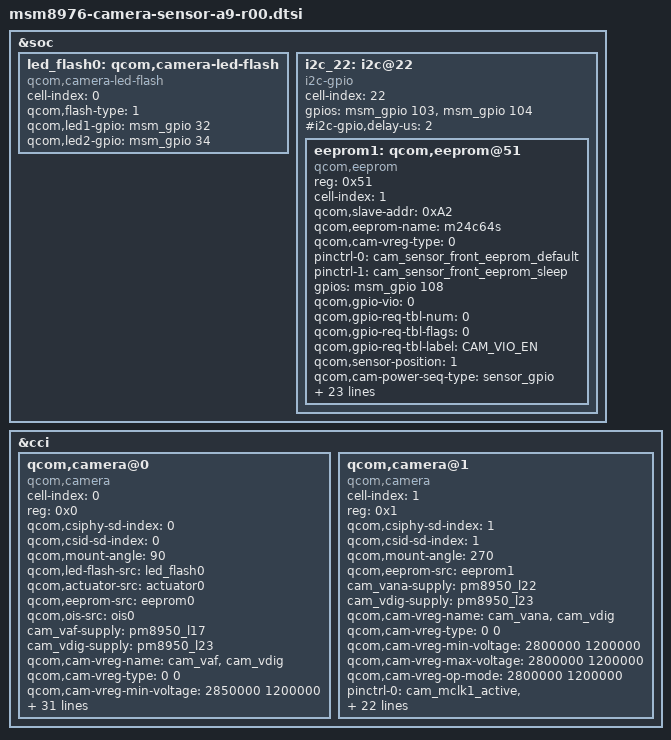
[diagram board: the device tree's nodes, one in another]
/*
 * Copyright (c) 2015, The Linux Foundation. All rights reserved.
 *
 * This program is free software; you can redistribute it and/or modify
 * it under the terms of the GNU General Public License version 2 and
 * only version 2 as published by the Free Software Foundation.
 *
 * This program is distributed in the hope that it will be useful,
 * but WITHOUT ANY WARRANTY; without even the implied warranty of
 * MERCHANTABILITY or FITNESS FOR A PARTICULAR PURPOSE.  See the
 * GNU General Public License for more details.
 */

&soc {

    led_flash0: qcom,camera-led-flash {
	cell-index = <0>;
	compatible = "qcom,camera-led-flash";
	qcom,flash-type = <1>;
	qcom,led1-gpio = <&msm_gpio 32 0x00>;
	qcom,led2-gpio = <&msm_gpio 34 0x00>;
    };
    i2c_22: i2c@22 {
	cell-index = <22>;
        compatible = "i2c-gpio";
	gpios = <&msm_gpio 103 0 /* sda */
                 &msm_gpio 104 0 /* scl */
		 >;
        #i2c-gpio,delay-us = <2>;
        #address-cells = <1>;
        #size-cells = <0>;

	eeprom1: qcom,eeprom@51 {
		 compatible = "qcom,eeprom";
		 reg = <0x51>;
		 cell-index = <1>;
		 qcom,slave-addr = <0xA2>;
		 qcom,eeprom-name = "m24c64s";
		 qcom,cam-vreg-type = <0>;
		 pinctrl-names = "cam_default", "cam_suspend";
		 pinctrl-0 = <&cam_sensor_front_eeprom_default>;
		 pinctrl-1 = <&cam_sensor_front_eeprom_sleep>;
		 gpios = <&msm_gpio 108 0>;
		 qcom,gpio-vio = <0>;
		 qcom,gpio-req-tbl-num = <0>;
		 qcom,gpio-req-tbl-flags = <0>;
		 qcom,gpio-req-tbl-label = "CAM_VIO_EN";
		 qcom,sensor-position = <1>;
		 qcom,cam-power-seq-type = "sensor_gpio";
		 qcom,cam-power-seq-val = "sensor_gpio_vio";
		 qcom,cam-power-seq-cfg-val = <1>;
		 qcom,cam-power-seq-delay =   <1>;
		 qcom,num-blocks = <6>;
		 qcom,page0 = <0 0x0 0 0x0 0 0>;
		 qcom,poll0 = <0 0x0 0 0x0 0 0>;
		 qcom,mem0 = <0x60 0x0 2 0 1 0>;
		 qcom,page1 = <0 0x0 0 0x0 0 0>;
		 qcom,poll1 = <0 0x0 0 0x0 0 0>;
		 qcom,mem1 = <4 0xFC 2 0 1 0>;
		 qcom,page2 = <0 0x0 0 0x0 0 0>;
		 qcom,poll2 = <0 0x0 0 0x0 0 0>;
		 qcom,mem2 = <0x20 0x200 2 0 1 0>;
		 qcom,page3 = <0 0x0 0 0x0 0 0>;
		 qcom,poll3 = <0 0x0 0 0x0 0 0>;
		 qcom,mem3 = <4 0x2FC 2 0 1 0>;
		 qcom,page4 = <0 0x0 0 0x0 0 0>;
		 qcom,poll4 = <0 0x0 0 0x0 0 0>;
		 qcom,mem4 = <0x700 0x300 2 0 1 0>;
		 qcom,page5 = <0 0x0 0 0x0 0 0>;
		 qcom,poll5 = <0 0x0 0 0x0 0 0>;
		 qcom,mem5 = <4 0xAFC 2 0 1 0>;
		 qcom,total-size = <0xB00>;

	         };
	};
};

&cci {

  qcom,camera@0 {
    cell-index = <0>;
    compatible = "qcom,camera";
    reg = <0x0>;
    qcom,csiphy-sd-index = <0>;
    qcom,csid-sd-index = <0>;
    qcom,mount-angle = <90>;
    qcom,led-flash-src = <&led_flash0>;
    qcom,actuator-src = <&actuator0>;
    qcom,eeprom-src = <&eeprom0>;
    qcom,ois-src = <&ois0>;
    cam_vaf-supply = <&pm8950_l17>;
    cam_vdig-supply = <&pm8950_l23>;
    qcom,cam-vreg-name = "cam_vaf", "cam_vdig";
    qcom,cam-vreg-type = <0 0>;
    qcom,cam-vreg-min-voltage = <2850000 1200000>;
    qcom,cam-vreg-max-voltage = <2850000 1200000>;
    qcom,cam-vreg-op-mode =     <2850000 1200000>;
    pinctrl-names = "cam_default", "cam_suspend";
    pinctrl-0 = <&cam_mclk0_active &cam_rear_sensor_active>;
    pinctrl-1 = <&cam_mclk0_sleep &cam_rear_sensor_sleep>;
    gpios = <&msm_gpio 26 0>, <&msm_gpio 129 0>,<&msm_gpio 108 0>,<&msm_gpio 126 0>,
            <&msm_gpio 35 0>,<&msm_gpio 36 0>;

    qcom,gpio-reset = <1>;
    qcom,gpio-vio = <2>;
    qcom,gpio-vana = <3>;
    qcom,gpio-custom1 = <4>;
    qcom,gpio-custom2 = <5>;
    qcom,gpio-req-tbl-num   = <0 1 2 3 4 5>;
    qcom,gpio-req-tbl-flags = <1 0 0 0 0 0>;
    qcom,gpio-req-tbl-label = "CAMIF_MCLK0", "CAM_RESET0", "CAM_VIO_EN","CAM_VANA", "CAM_OIS_EN", "CAM_OIS_RESET";
    qcom,sensor-position = <0>;
    qcom,sensor-mode = <0>;
    qcom,cci-master = <0>;
    status = "ok";
    clocks = <&clock_gcc clk_mclk0_clk_src>,
        <&clock_gcc clk_gcc_camss_mclk0_clk>;
       /* <&clock_gcc clk_bb_clk2>;*/
    clock-names = "cam_src_clk", "cam_clk"; /*"bb_clk2";*/
    cam,isp = <0>;                  // 0 : INT , 1 : EXT , 2 : SOC
    cam,cal_memory = <2>;           // 0 : N , 1 : FROM , 2 : EEPROM , 3 : OTP
    cam,read_version = <0>;         // 0 : SYSFS , 1 : CAMON
    cam,core_voltage = <0>;         // 0 : N , 1 : Y
    cam,upgrade = <0>;              // 0 : N , 1 : SYSFS , 2 : CAMON
    cam,companion_chip = <0>;       // 0 : N , 1 : Y
    cam,ois = <1>;                  // 0 : N , 1 : Y
  };

  qcom,camera@1 {
    cell-index = <1>;
    compatible = "qcom,camera";
    reg = <0x1>;
    qcom,csiphy-sd-index = <1>;
    qcom,csid-sd-index = <1>;
    qcom,mount-angle = <270>;
    qcom,eeprom-src = <&eeprom1>;
    cam_vana-supply = <&pm8950_l22>;
    cam_vdig-supply = <&pm8950_l23>;
    qcom,cam-vreg-name = "cam_vana", "cam_vdig";
    qcom,cam-vreg-type = <0 0>;
    qcom,cam-vreg-min-voltage = <2800000 1200000>;
    qcom,cam-vreg-max-voltage = <2800000 1200000>;
    qcom,cam-vreg-op-mode =     <2800000 1200000>;
    pinctrl-names = "cam_default", "cam_suspend";
    pinctrl-0 = <&cam_mclk1_active &cam_front_sensor_active>;
    pinctrl-1 = <&cam_mclk1_sleep &cam_front_sensor_sleep>;
    gpios = <&msm_gpio 27 0>,
            <&msm_gpio 130 0>,
            <&msm_gpio 108 0>;
    qcom,gpio-reset = <1>;
    qcom,gpio-vio = <2>;
    qcom,gpio-req-tbl-num = <0 1 2>;
    qcom,gpio-req-tbl-flags = <1 0 0>;
    qcom,gpio-req-tbl-label = "CAMIF_MCLK1", "CAM_RESET1", "CAM_VIO_EN";
    qcom,sensor-position = <1>;
    qcom,sensor-mode = <0>;
    qcom,cci-master = <0>;
    status = "ok";
    clocks = <&clock_gcc clk_mclk1_clk_src>,
        <&clock_gcc clk_gcc_camss_mclk1_clk>;
    clock-names = "cam_src_clk", "cam_clk";
    cam,isp = <0>;                  // 0 : INT , 1 : EXT , 2 : SOC
    cam,cal_memory = <2>;           // 0 : N , 1 : FROM , 2 : EEPROM , 3 : OTP
    cam,read_version = <0>;         // 0 : SYSFS , 1 : CAMON
    cam,core_voltage = <0>;         // 0 : N , 1 : Y
    cam,upgrade = <0>;              // 0 : N , 1 : SYSFS , 2 : CAMON
    cam,companion_chip = <0>;       // 0 : N , 1 : Y
    cam,ois = <0>;                  // 0 : N , 1 : Y
  };
};
